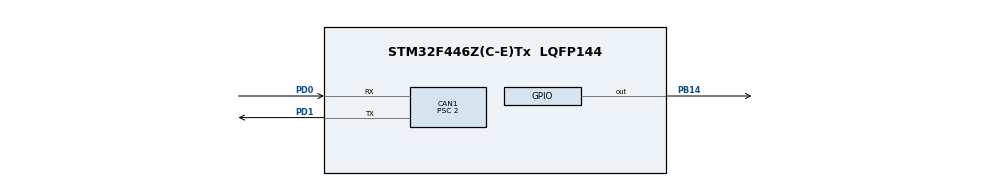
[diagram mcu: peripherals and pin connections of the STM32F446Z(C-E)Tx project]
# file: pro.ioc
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CAN1.ABOM=ENABLE
CAN1.AWUM=ENABLE
CAN1.BS1=CAN_BS1_13TQ
CAN1.BS2=CAN_BS2_2TQ
CAN1.CalculateBaudRate=500000
CAN1.CalculateTimeBit=2000
CAN1.CalculateTimeQuantum=125.0
CAN1.NART=ENABLE
CAN1.Prescaler=2
Mcu.Family=STM32F4
Mcu.Name=STM32F446Z(C-E)Tx
Mcu.Package=LQFP144
NVIC.CAN1_RX0_IRQn=true\:0\:0\:false\:false\:true\:true\:true\:true
NVIC.PriorityGroup=NVIC_PRIORITYGROUP_4
PB14.Signal=GPIO_Output
PD0.Mode=CAN_Activate
PD0.Signal=CAN1_RX
PD1.Mode=CAN_Activate
PD1.Signal=CAN1_TX
ProjectManager.HeapSize=0x200
ProjectManager.StackSize=0x400
ProjectManager.TargetToolchain=STM32CubeIDE
RCC.CortexFreq_Value=16000000
RCC.USBFreq_Value=96000000
RCC.VCOOutputFreq_Value=192000000
board=custom

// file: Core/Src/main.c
/* USER CODE BEGIN Header */
/**
  ******************************************************************************
  * @file           : main.c
  * @brief          : Main program body
  ******************************************************************************
  * @attention
  *
  * Copyright (c) 2026 STMicroelectronics.
  * All rights reserved.
  *
  * This software is licensed under terms that can be found in the LICENSE file
  * in the root directory of this software component.
  * If no LICENSE file comes with this software, it is provided AS-IS.
  *
  ******************************************************************************
  */
/* USER CODE END Header */
#include "main.h"
#include "can.h"
#include "gpio.h"

/* USER CODE BEGIN PV */
#define RX_BUF_SIZE 16

typedef struct
{
  CAN_RxHeaderTypeDef header;
  uint8_t data[8];
} CAN_Frame_t;

volatile uint8_t rxWr = 0;
volatile uint8_t rxRd = 0;
uint32_t lastTxTick = 0;
uint16_t txStdId = 0x100;
uint8_t  txCounter = 0;
CAN_Frame_t rxBuf[RX_BUF_SIZE];

/* USER CODE END PV */

void SystemClock_Config(void);
/* USER CODE BEGIN PFP */
void CAN_Send_Incremental(void);
uint8_t CAN_Read(CAN_Frame_t *out);
/* USER CODE END PFP */

int main(void)
{

  /* MCU Configuration--------------------------------------------------------*/

  /* Reset of all peripherals, Initializes the Flash interface and the Systick. */
  HAL_Init();

  /* Configure the system clock */
  SystemClock_Config();

  /* Initialize all configured peripherals */
  MX_GPIO_Init();
  MX_CAN1_Init();
  /* USER CODE BEGIN 2 */
  CAN_FilterTypeDef filter;

    filter.FilterBank = 0;
    filter.FilterMode = CAN_FILTERMODE_IDMASK;
    filter.FilterScale = CAN_FILTERSCALE_32BIT;
    filter.FilterIdHigh = 0x0000;
    filter.FilterIdLow  = 0x0000;
    filter.FilterMaskIdHigh = 0x0000;
    filter.FilterMaskIdLow  = 0x0000;
    filter.FilterFIFOAssignment = CAN_RX_FIFO0;
    filter.FilterActivation = ENABLE;
    filter.SlaveStartFilterBank = 14;

    HAL_CAN_ConfigFilter(&hcan1, &filter);
    HAL_CAN_Start(&hcan1);
    HAL_CAN_ActivateNotification(&hcan1, CAN_IT_RX_FIFO0_MSG_PENDING);

  /* USER CODE END 2 */

  /* Infinite loop */
  while (1)
  {

    /* USER CODE BEGIN 3 */
	  if (HAL_GetTick() - lastTxTick >= 500)
	      {
	          lastTxTick = HAL_GetTick();
	          CAN_Send_Incremental();
	      }

	      CAN_Frame_t rx;
	      if (CAN_Read(&rx))
	      {
	    	  HAL_GPIO_TogglePin(GPIOB, GPIO_PIN_14);

	        }

  }
  /* USER CODE END 3 */
}

void SystemClock_Config(void)
{
  RCC_OscInitTypeDef RCC_OscInitStruct = {0};
  RCC_ClkInitTypeDef RCC_ClkInitStruct = {0};

  /** Configure the main internal regulator output voltage
  */
  __HAL_RCC_PWR_CLK_ENABLE();
  __HAL_PWR_VOLTAGESCALING_CONFIG(PWR_REGULATOR_VOLTAGE_SCALE3);

  /** Initializes the RCC Oscillators according to the specified parameters
  * in the RCC_OscInitTypeDef structure.
  */
  RCC_OscInitStruct.OscillatorType = RCC_OSCILLATORTYPE_HSI;
  RCC_OscInitStruct.HSIState = RCC_HSI_ON;
  RCC_OscInitStruct.HSICalibrationValue = RCC_HSICALIBRATION_DEFAULT;
  RCC_OscInitStruct.PLL.PLLState = RCC_PLL_NONE;
  if (HAL_RCC_OscConfig(&RCC_OscInitStruct) != HAL_OK)
  {
    Error_Handler();
  }

  /** Initializes the CPU, AHB and APB buses clocks
  */
  RCC_ClkInitStruct.ClockType = RCC_CLOCKTYPE_HCLK|RCC_CLOCKTYPE_SYSCLK
                              |RCC_CLOCKTYPE_PCLK1|RCC_CLOCKTYPE_PCLK2;
  RCC_ClkInitStruct.SYSCLKSource = RCC_SYSCLKSOURCE_HSI;
  RCC_ClkInitStruct.AHBCLKDivider = RCC_SYSCLK_DIV1;
  RCC_ClkInitStruct.APB1CLKDivider = RCC_HCLK_DIV1;
  RCC_ClkInitStruct.APB2CLKDivider = RCC_HCLK_DIV1;

  if (HAL_RCC_ClockConfig(&RCC_ClkInitStruct, FLASH_LATENCY_0) != HAL_OK)
  {
    Error_Handler();
  }
}

/* USER CODE BEGIN 4 */
uint8_t CAN_Read(CAN_Frame_t *out)
{
    if (rxRd == rxWr)
        return 0; // buffer empty

    *out = rxBuf[rxRd];
    rxRd = (rxRd + 1) % RX_BUF_SIZE;
    return 1;
}
void CAN_Send_Incremental(void)
{
    CAN_TxHeaderTypeDef txHeader;
    uint32_t txMailbox;
    uint8_t txData[8];
    for (uint8_t i = 0; i < 8; i++)
    {
        txData[i] = txCounter + i;
    }

    txHeader.StdId = txStdId;
    txHeader.IDE   = CAN_ID_STD;
    txHeader.RTR   = CAN_RTR_DATA;
    txHeader.DLC   = 8;
    txHeader.TransmitGlobalTime = DISABLE;

    if (HAL_CAN_GetTxMailboxesFreeLevel(&hcan1) > 0)
    {
        HAL_CAN_AddTxMessage(&hcan1, &txHeader, txData, &txMailbox);

        /* Increment for next frame */
        txCounter++;
        txStdId++;

        /* Wrap safely */
        if (txStdId > 0x7FF)
            txStdId = 0x100;
    }
}
void HAL_CAN_RxFifo0MsgPendingCallback(CAN_HandleTypeDef *hcan)
{
    CAN_Frame_t *slot = &rxBuf[rxWr];

    if (HAL_CAN_GetRxMessage(hcan, CAN_RX_FIFO0,
                             &slot->header, slot->data) == HAL_OK)
    {
        uint8_t next = (rxWr + 1) % RX_BUF_SIZE;

        if (next != rxRd)   // buffer not full
        {
            rxWr = next;
        }
    }
}

/* USER CODE END 4 */

void Error_Handler(void)
{
  __disable_irq();
  while (1)
  {
  }
}
